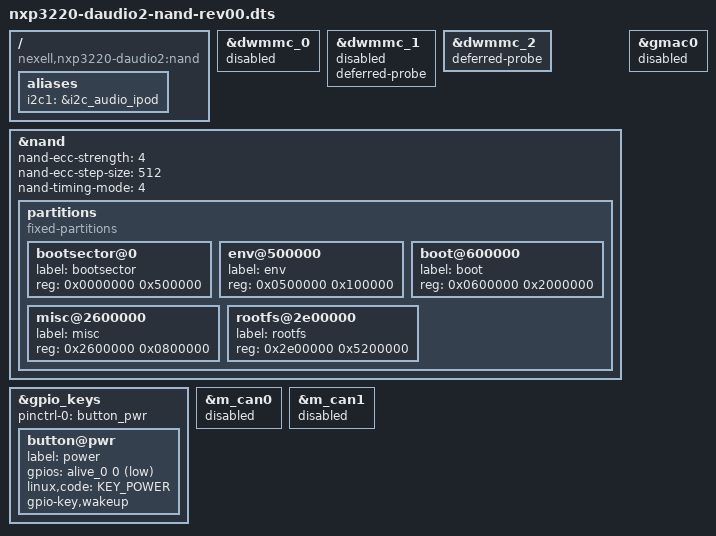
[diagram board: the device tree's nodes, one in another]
// SPDX-License-Identifier: (GPL-2.0+ OR MIT)
/*
 * Copyright (C) 2018  Nexell Co., Ltd.
 * Author: JungHyun, Kim <jhkim@nexell.co.kr>
 */

/dts-v1/;

#include "nxp3220-evb2-common.dtsi"

/ {
	compatible = "nexell,nxp3220-daudio2:nand", "nexell,nxp3220";
        aliases {
                i2c1 = &i2c_audio_ipod;
        };
};

&dwmmc_0 {
	status = "disabled";
};

&dwmmc_1 {
	deferred-probe;
	status = "disabled";
};

&dwmmc_2 {
	deferred-probe;
	status = "okay";
};

&nand {
	status = "okay";

	nand-ecc-strength = <4>;
	nand-ecc-step-size = <512>;
	nand-timing-mode = <4>;

	partitions {
		compatible = "fixed-partitions";
		#address-cells = <1>;
		#size-cells = <1>;

		bootsector@0 {
			label = "bootsector";
			reg = <0x0000000 0x500000>;
		     /*	read-only; */
		};

		env@500000 {
			label = "env";
			reg = <0x0500000 0x100000>;
		     /*	read-only; */
		};

		boot@600000 {
			label = "boot";
			reg = <0x0600000 0x2000000>;
		};

		misc@2600000 {
			label = "misc";
			reg = <0x2600000 0x0800000>;
		};

		rootfs@2e00000 {
			label = "rootfs";
			reg = <0x2e00000 0x5200000>;
		};
	};
};

&gmac0 {
	status = "disabled";
};

&gpio_keys {
	pinctrl-names = "default";
	pinctrl-0 = <&button_pwr>;

	button@pwr {
		label = "power";
		gpios = <&alive_0 0 GPIO_ACTIVE_LOW>;
		linux,code = <KEY_POWER>;
		gpio-key,wakeup;
	};
};

&m_can0 {
	status = "disabled";
};

&m_can1 {
	status = "disabled";
};
